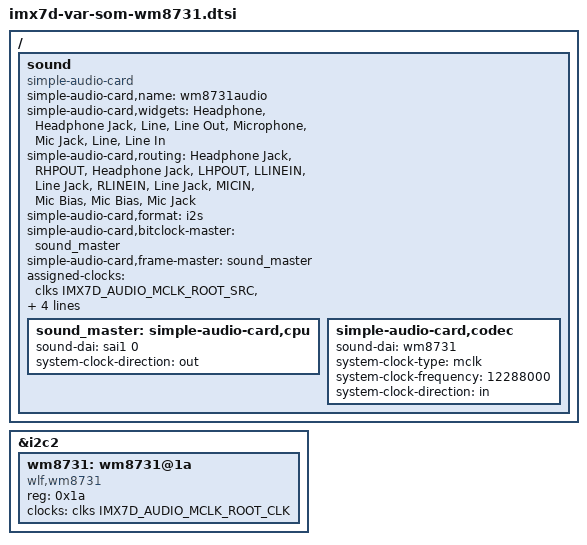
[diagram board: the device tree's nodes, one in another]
/*
 * Copyright (C) 2024 Variscite Ltd.
 *
 * This program is free software; you can redistribute it and/or modify
 * it under the terms of the GNU General Public License version 2 as
 * published by the Free Software Foundation.
 */

/ {
	/delete-node/ sound;

	sound {
		compatible = "simple-audio-card";
		simple-audio-card,name = "wm8731audio";
		simple-audio-card,widgets =
			"Headphone", "Headphone Jack",
			"Line", "Line Out",
			"Microphone", "Mic Jack",
			"Line", "Line In";
		simple-audio-card,routing =
			"Headphone Jack", "RHPOUT",
			"Headphone Jack", "LHPOUT",
			"LLINEIN", "Line Jack",
			"RLINEIN", "Line Jack",
			"MICIN", "Mic Bias",
			"Mic Bias", "Mic Jack";
		simple-audio-card,format = "i2s";
		simple-audio-card,bitclock-master = <&sound_master>;
		simple-audio-card,frame-master = <&sound_master>;
		/*simple-audio-card,bitclock-inversion;*/

		assigned-clocks = <&clks IMX7D_AUDIO_MCLK_ROOT_SRC>,
			          <&clks IMX7D_AUDIO_MCLK_ROOT_CLK>;
		assigned-clock-parents = <&clks IMX7D_PLL_AUDIO_POST_DIV>;
		assigned-clock-rates = <0>, <12288000>;

		sound_master: simple-audio-card,cpu {
			sound-dai = <&sai1 0>;
			system-clock-direction = "out";
		};

		simple-audio-card,codec {
			sound-dai = <&wm8731>;
			system-clock-type = "mclk";
			system-clock-frequency = <12288000>;
			system-clock-direction = "in";
		};
	};
};

&i2c2 {
	/delete-node/ wm8904@1a;

	wm8731: wm8731@1a {
		#sound-dai-cells = <0>;
		compatible = "wlf,wm8731";
		reg = <0x1a>;
		clocks = <&clks IMX7D_AUDIO_MCLK_ROOT_CLK>;
		clock-names = "mclk";
		status = "okay";
	};
};
